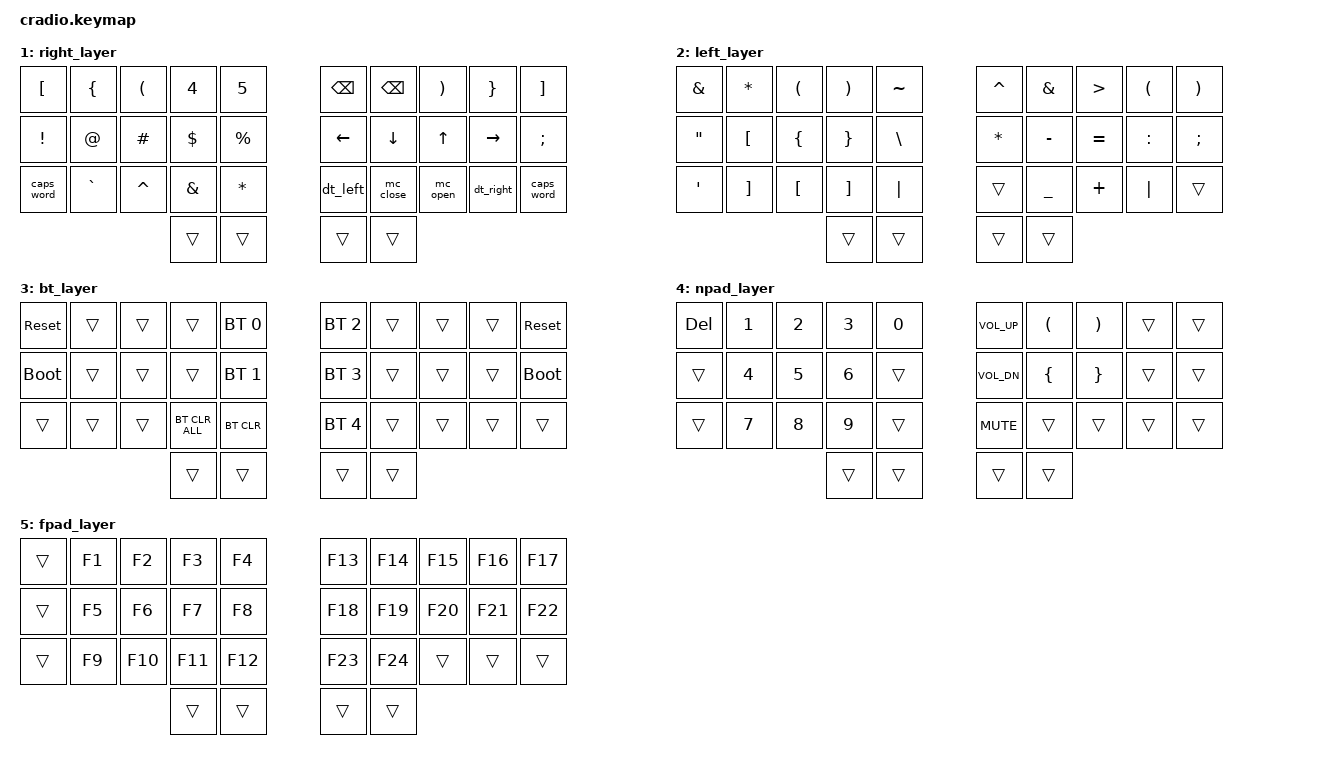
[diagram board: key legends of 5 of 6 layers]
// Copyright (c) 2022 The ZMK Contributors
// SPDX-License-Identifier: MIT


#include "keypos_34keys.h"
#include <behaviors.dtsi>
#include <dt-bindings/zmk/bt.h>
#include <dt-bindings/zmk/keys.h>



// Home row mods macro
// left shift causes a lot of misfirfes 
#define HRML(k1,k2,k3,k4) &kp k1  &mt LCTRL k2  &mt LALT  k3  &mt LGUI  k4
#define HRMR(k1,k2,k3,k4) &mt RGUI  k1  &mt RALT  k2  &mt RCTRL k3  &mt RSHFT k4
#define HYP(k1) &mt LS(LC(LA(LGUI))) k1
#define MEH(k1) &mt LS(LC(LA)) k1

#define BASE 0
#define RIG  1
#define LEF  2
#define BT   3
#define NPAD 4
#define FPAD 5


#define TAPPING_TERM 240
#define SHIFT_TAP_MS 180
#define QUICK_TAP_MS 150
#define SHORTCUT_MS  270
#define PRIOR_IDLE   150


&mt {
    flavor = "balanced";
    tapping-term-ms = <TAPPING_TERM>;
    quick-tap-ms = <QUICK_TAP_MS>;
    require-prior-idle-ms = <PRIOR_IDLE>;
};



/*                              34 KEY MATRIX / LAYOUT MAPPING

  ╭────────────────────┬────────────────────╮ ╭─────────────────────┬─────────────────────╮
  │  0   1   2   3   4 │  5   6   7   8   9 │ │ LT4 LT3 LT2 LT1 LT0 │ RT0 RT1 RT2 RT3 RT4 │
  │ 10  11  12  13  14 │ 15  16  17  18  19 │ │ LM4 LM3 LM2 LM1 LM0 │ RM0 RM1 RM2 RM3 RM4 │
  │ 20  21  22  23  24 │ 25  26  27  28  29 │ │ LB4 LB3 LB2 LB1 LB0 │ RB0 RB1 RB2 RB3 RB4 │
  ╰───────╮     30  31 │ 32  33     ╭───────╯ ╰───────╮     LH1 LH0 │ RH0 RH1     ╭───────╯
          ╰────────────┴────────────╯                 ╰─────────────┴─────────────╯             */





#define COMBO(name, kp, pos)               \
combo_##name {                             \
    timeout-ms            = <30>;          \
    require-prior-idle-ms = <TAPPING_TERM>;\
    bindings              = <kp>;          \
    key-positions         = <pos>;         \
    layers                = <0 1>;         \
};


/ {

	combos {
        compatible = "zmk,combos";
	
        COMBO(combo_esfc, &kp ESC, 2 3)
        COMBO(combo_cut, &kp LG(X),20 21)
 		COMBO(combo_cpy, &kp LG(C), 21 22) 
        COMBO(combo_pst, &kp LG(V), 22 23)
        COMBO(combo_pst_wo, &kp LS(LG(V)), 22 24)
        COMBO(combo_pst_wok, &kp LA(LS(LG(V))),23 24)
 		COMBO(combo_app_chgr, &kp LG(SPACE),12 13)
        COMBO(combo_lasso, &kp LG(LC(LS(N4))), 11 12)
        COMBO(combo_returnR, &kp RETURN,32 29)
        COMBO(combo_returnL, &kp RETURN,31 20)

        COMBO(combo_bspc, &kp BSPC, 32 9)
        COMBO(combo_indt, &vs_idt, 6 7)

        COMBO(combo_bsft, &bs_ft, 3 4)
        COMBO(combo_bszt, &bs_zt, 13 14)

        COMBO(combo_cpsnip, &kp LS(LG(N2)), 1 2)
    };



#define MACRO(name, keys)                  \
name: name {                               \
    compatible     = "zmk,behavior-macro"; \
    #binding-cells = <0>;                  \
    bindings       = <keys>;               \
};


// this doesnt work, error on build
/// {
//    macros {
//        MACRO(vs_idt, &kp LC(K) &kp LC(D) )
//   };
//};


ZMK_MACRO(vs_idt,
        wait-ms = <10>;
        tap-ms = <40>;
        bindings = <&kp LC(K) &kp LC(D)>;
    )

ZMK_MACRO(bs_ft,
        wait-ms = <10>;
        tap-ms = <20>;
        bindings = <&kp N1 &kp N0 &kp TAB >;
    )

ZMK_MACRO(bs_zt,
        wait-ms = <10>;
        tap-ms = <20>;
        bindings = <&kp N0 &kp TAB >;
    )

ZMK_MACRO(dt_left,
        wait-ms = <10>;
        tap-ms = <20>;
        bindings = <&kp LC(LEFT)>;
)

ZMK_MACRO(dt_right,
        wait-ms = <10>;
        tap-ms = <20>;
        bindings = <&kp LC(RIGHT)>;
)


ZMK_MACRO(mc_open,
        wait-ms = <10>;
        tap-ms = <20>;
        bindings = <&kp LC(UP)>;
)


ZMK_MACRO(mc_close,
        wait-ms = <10>;
        tap-ms = <20>;
        bindings = <&kp LC(DOWN)>;
)

//   behaviors {
//        ht: hold_tap {
//            compatible = "zmk,behavior-hold-tap";
//            #binding-cells = <2>;
//            flavor = "tap-preferred";
//            tapping-term-ms = <220>;
//            quick-tap-ms = <150>;
//            require-prior-idle-ms = <100>;
//            bindings = <&kp>, <&kp>;
//        };
//    };

    conditional_layers {
        compatible = "zmk,conditional-layers";
        tri_layer {
            if-layers = <1 2>;
            then-layer = <3>;
        };
    };

    keymap {
        compatible = "zmk,keymap";
        default_layer {
            bindings = <
        //╭──────────┬──────────┬──────────┬──────────┬──────────╮   ╭──────────┬──────────┬──────────┬──────────┬──────────╮
        //│ Q (f pad)│  W       │  E       │  R       │  T       │   │  Y       │  U       │  I       │  O       │   P      │           
        //├──────────┼──────────┼──────────┼──────────┼──────────┤   ├──────────┼──────────┼──────────┼──────────┼──────────┤
        //│  A       │  S       │  D       │  F       │  G       │   │  H       │  J       │  K       │  L       │   ;      │            
        //├──────────┼──────────┼──────────┼──────────┼──────────┤   ├──────────┼──────────┼──────────┼──────────┼──────────┤
        //│  Z       │  X       │  C       │  V       │  B       │   │  N       │  M       │ , <      │ . >      │ /?(enter)│    
        //╰──────────┴──────────┴──────────┼──────────┼──────────┤   ├──────────┼──────────┼──────────┴──────────┴──────────╯                          
        //                                 │ left/TAB │  SPACE   │   │   SHIFT  │right/bspc│ 
        //                                 ╰──────────┴──────────╯   ╰──────────┴──────────╯
        
         &lt FPAD Q   &kp W      &kp E      &kp R      &mt CLCK T        &kp Y      &kp U      &kp I      &kp O      &kp P
         HRML(A,        S,         D,          F)      &kp G             &kp H      HRMR(J,        K,         L,        SEMI)
         &mt LSHFT Z  &kp X      &kp C      &kp V      HYP(B)             HYP(N)     &kp M      &kp COMMA  &kp DOT    &kp FSLH
                                     &lt LEF TAB     &lt NPAD SPACE    &kp RSHFT  &lt RIG BSPC

            >;
        };


        right_layer {
            bindings = <
        //╭──────────┬──────────┬──────────┬──────────┬──────────╮   ╭──────────┬──────────┬──────────┬──────────┬──────────╮
        //│    [     │    {     │    (     │     4    │     5    │   │   BSPC   │  BSPC    │     )    │    }     │     ]    │
        //├──────────┼──────────┼──────────┼──────────┼──────────┤   ├──────────┼──────────┼──────────┼──────────┼──────────┤
        //│      !   │    @     │   #      │    $     │    %     │   │   left   │  down    │    up    │  right   │   ;      │
        //├──────────┼──────────┼──────────┼──────────┼──────────┤   ├──────────┼──────────┼──────────┼──────────┼──────────┤
        //│ CAP word │    `~    │    ^     │    &     │    *     │   │   HOME   │ PG DN    │   PG UP  │   END    │ CAP word │
        //╰──────────┴──────────┴──────────┼──────────┼──────────┤   ├──────────┼──────────┼──────────┴──────────┴──────────╯
        //                                 │          │          │   │          │          │ 
        //                                 ╰──────────┴──────────╯   ╰──────────┴──────────╯
        
        &kp LBKT     &kp LBRC    &kp LPAR    &kp N4     &kp N5         &kp BSPC    &kp BSPC   &kp RPAR   &kp RBRC   &kp RBKT
        &kp EXCL     &kp AT      &kp HASH    &kp DLLR   &kp PRCNT      &kp LEFT    &kp DOWN   &kp UP     &kp RIGHT  &kp SEMI
        &caps_word   &kp GRAVE   &kp CARET   &kp AMPS   &kp ASTRK      &dt_left    &mc_close  &mc_open   &dt_right    &caps_word
                                             &trans     &trans         &trans      &trans
            >;
        };


        left_layer {
            bindings = <
        //╭──────────┬──────────┬──────────┬──────────┬──────────╮   ╭──────────┬──────────┬──────────┬──────────┬──────────╮
        //│    &     │    *     │    (     │     )    │    ~     │   │  ^       │    &     │    >     │    (     │    )     │
        //├──────────┼──────────┼──────────┼──────────┼──────────┤   ├──────────┼──────────┼──────────┼──────────┼──────────┤
        //│    "     │    [     │    {     │    }     │   \      │   │  *       │  -       │  =       │    :     │   ;      │
        //├──────────┼──────────┼──────────┼──────────┼──────────┤   ├──────────┼──────────┼──────────┼──────────┼──────────┤
        //│    '     │    ]     │    [     │    ]     │   |      │   │  (n)     │  _       │  +       │  │       │          │
        //╰──────────┴──────────┴──────────┼──────────┼──────────┤   ├──────────┼──────────┼──────────┴──────────┴──────────╯
        //                                 ╰──────────┴──────────╯   ╰──────────┴──────────╯
        
        &kp AMPS   &kp STAR   &kp LPAR    &kp RPAR   &kp TILDE        &kp CARET   &kp AMPS   &kp GT     &kp LPAR   &kp RPAR
        &kp DQT    &kp LBKT   &kp LBRC    &kp RBRC   &kp BSLH         &kp ASTRK   &kp MINUS  &kp EQUAL  &kp COLON  &kp SEMI
        &kp SQT    &kp RBKT   &kp LBKT    &kp RBKT   &kp PIPE         &trans      &kp UNDER  &kp PLUS   &kp PIPE   &trans
                                          &trans     &trans           &trans      &trans
            >;
        };

        bt_layer {
            bindings = <
        //╭──────────┬──────────┬──────────┬──────────┬──────────╮     ╭──────────┬──────────┬──────────┬──────────┬──────────╮
        //│ RESET    │          │          │          │PROFILE 0 │     │ PROFILE 2│          │          │          │  RESET   │
        //├──────────┼──────────┼──────────┼──────────┼──────────┤     ├──────────┼──────────┼──────────┼──────────┼──────────┤
        //│BOOTLOADER│          │          │          │PROFILE 1 │     │ PROFILE 3│          │          │          │BOOTLOADER│
        //├──────────┼──────────┼──────────┼──────────┼──────────┤     ├──────────┼──────────┼──────────┼──────────┼──────────┤
        //│          │          │          │CLR BT ALL│ CLEAR BT │     │ PROFILE 4│          │          │          │          │
        //╰──────────┴──────────┴──────────┼──────────┼──────────┤     ├──────────┼──────────┼──────────┴──────────┴──────────╯
        //                                 ╰──────────┴──────────╯     ╰──────────┴──────────╯
        
        &sys_reset   &trans     &trans    &trans         &bt BT_SEL 0     &bt BT_SEL 2  &trans     &trans     &trans    &sys_reset
        &bootloader  &trans     &trans    &trans         &bt BT_SEL 1     &bt BT_SEL 3  &trans     &trans     &trans    &bootloader
        &trans       &trans     &trans    &bt BT_CLR_ALL &bt BT_CLR       &bt BT_SEL 4  &trans     &trans     &trans    &trans
                                          &trans         &trans           &trans        &trans

            >;
        };

        npad_layer {
            bindings = <
        //╭──────────┬──────────┬──────────┬──────────┬──────────╮   ╭──────────┬──────────┬──────────┬──────────┬──────────╮
        //│   del    │    1     │    2     │     3    │   0      │   │  Vol Up  │          │          │          │          │
        //├──────────┼──────────┼──────────┼──────────┼──────────┤   ├──────────┼──────────┼──────────┼──────────┼──────────┤
        //│          │    4     │    5     │     6    │          │   │  Vol Dwn │          │          │          │          │
        //├──────────┼──────────┼──────────┼──────────┼──────────┤   ├──────────┼──────────┼──────────┼──────────┼──────────┤
        //│          │    7     │   8      │     9    │          │   │  Mute    │          │          │          │          │
        //╰──────────┴──────────┴──────────┼──────────┼──────────┤   ├──────────┼──────────┼──────────┴──────────┴──────────╯
        //                                 ╰──────────┴──────────╯   ╰──────────┴──────────╯
        
        &kp DEL      &kp N1     &kp N2    &kp N3     &kp N0           &kp C_VOL_UP  &kp LPAR   &kp RPAR   &trans    &trans
        &trans       &kp N4     &kp N5    &kp N6     &trans           &kp C_VOL_DN  &kp LBRC   &kp RBRC   &trans    &trans
        &trans       &kp N7     &kp N8    &kp N9     &trans           &kp C_MUTE    &trans     &trans     &trans    &trans
                                          &trans     &trans           &trans        &trans

            >;
        };

        fpad_layer {
            bindings = <
        //╭──────────┬──────────┬──────────┬──────────┬──────────╮   ╭──────────┬──────────┬──────────┬──────────┬──────────╮
        //│   xxx    │   f1     │   f2     │    f3    │   f4     │   │   f13    │    f14   │  f15     │          │          │
        //├──────────┼──────────┼──────────┼──────────┼──────────┤   ├──────────┼──────────┼──────────┼──────────┼──────────┤
        //│          │   f5     │   f6     │    f7    │   f8     │   │  Vol Dwn │          │          │          │          │
        //├──────────┼──────────┼──────────┼──────────┼──────────┤   ├──────────┼──────────┼──────────┼──────────┼──────────┤
        //│          │   f9     │   f10    │    f11   │   f12    │   │  Mute    │          │          │          │          │
        //╰──────────┴──────────┴──────────┼──────────┼──────────┤   ├──────────┼──────────┼──────────┴──────────┴──────────╯
        //                                 ╰──────────┴──────────╯   ╰──────────┴──────────╯
        
        &trans       &kp F1     &kp F2    &kp F3     &kp F4           &kp F13     &kp F14    &kp F15     &kp F16    &kp F17
        &trans       &kp F5     &kp F6    &kp F7     &kp F8           &kp F18     &kp F19    &kp F20     &kp F21    &kp F22
        &trans       &kp F9     &kp F10   &kp F11    &kp F12          &kp F23     &kp F24    &trans      &trans     &trans
                                          &trans     &trans           &trans      &trans

            >;
        };
    };
};
